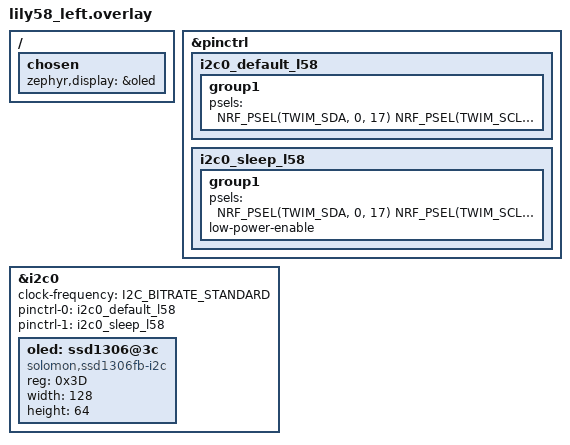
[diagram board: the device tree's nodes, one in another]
/ {
	chosen { zephyr,display = &oled; };
};

&pinctrl {
	i2c0_default_l58: i2c0_default_l58 {
		group1 {
			psels = <NRF_PSEL(TWIM_SDA, 0, 17) NRF_PSEL(TWIM_SCL, 0, 20)>;
		};
	};

	i2c0_sleep_l58: i2c0_sleep_l58 {
		group1 {
			psels = <NRF_PSEL(TWIM_SDA, 0, 17) NRF_PSEL(TWIM_SCL, 0, 20)>;
			low-power-enable;
		};
	};
};

&i2c0 {
	status = "okay";
	clock-frequency = <I2C_BITRATE_STANDARD>;
	pinctrl-0 = <&i2c0_default_l58>;
	pinctrl-1 = <&i2c0_sleep_l58>;
	pinctrl-names = "default", "sleep";

	oled: ssd1306@3c {
		compatible = "solomon,ssd1306fb-i2c";
		reg = <0x3D>;
		width = <128>;
		height = <64>;
		status = "okay";
	};
};
